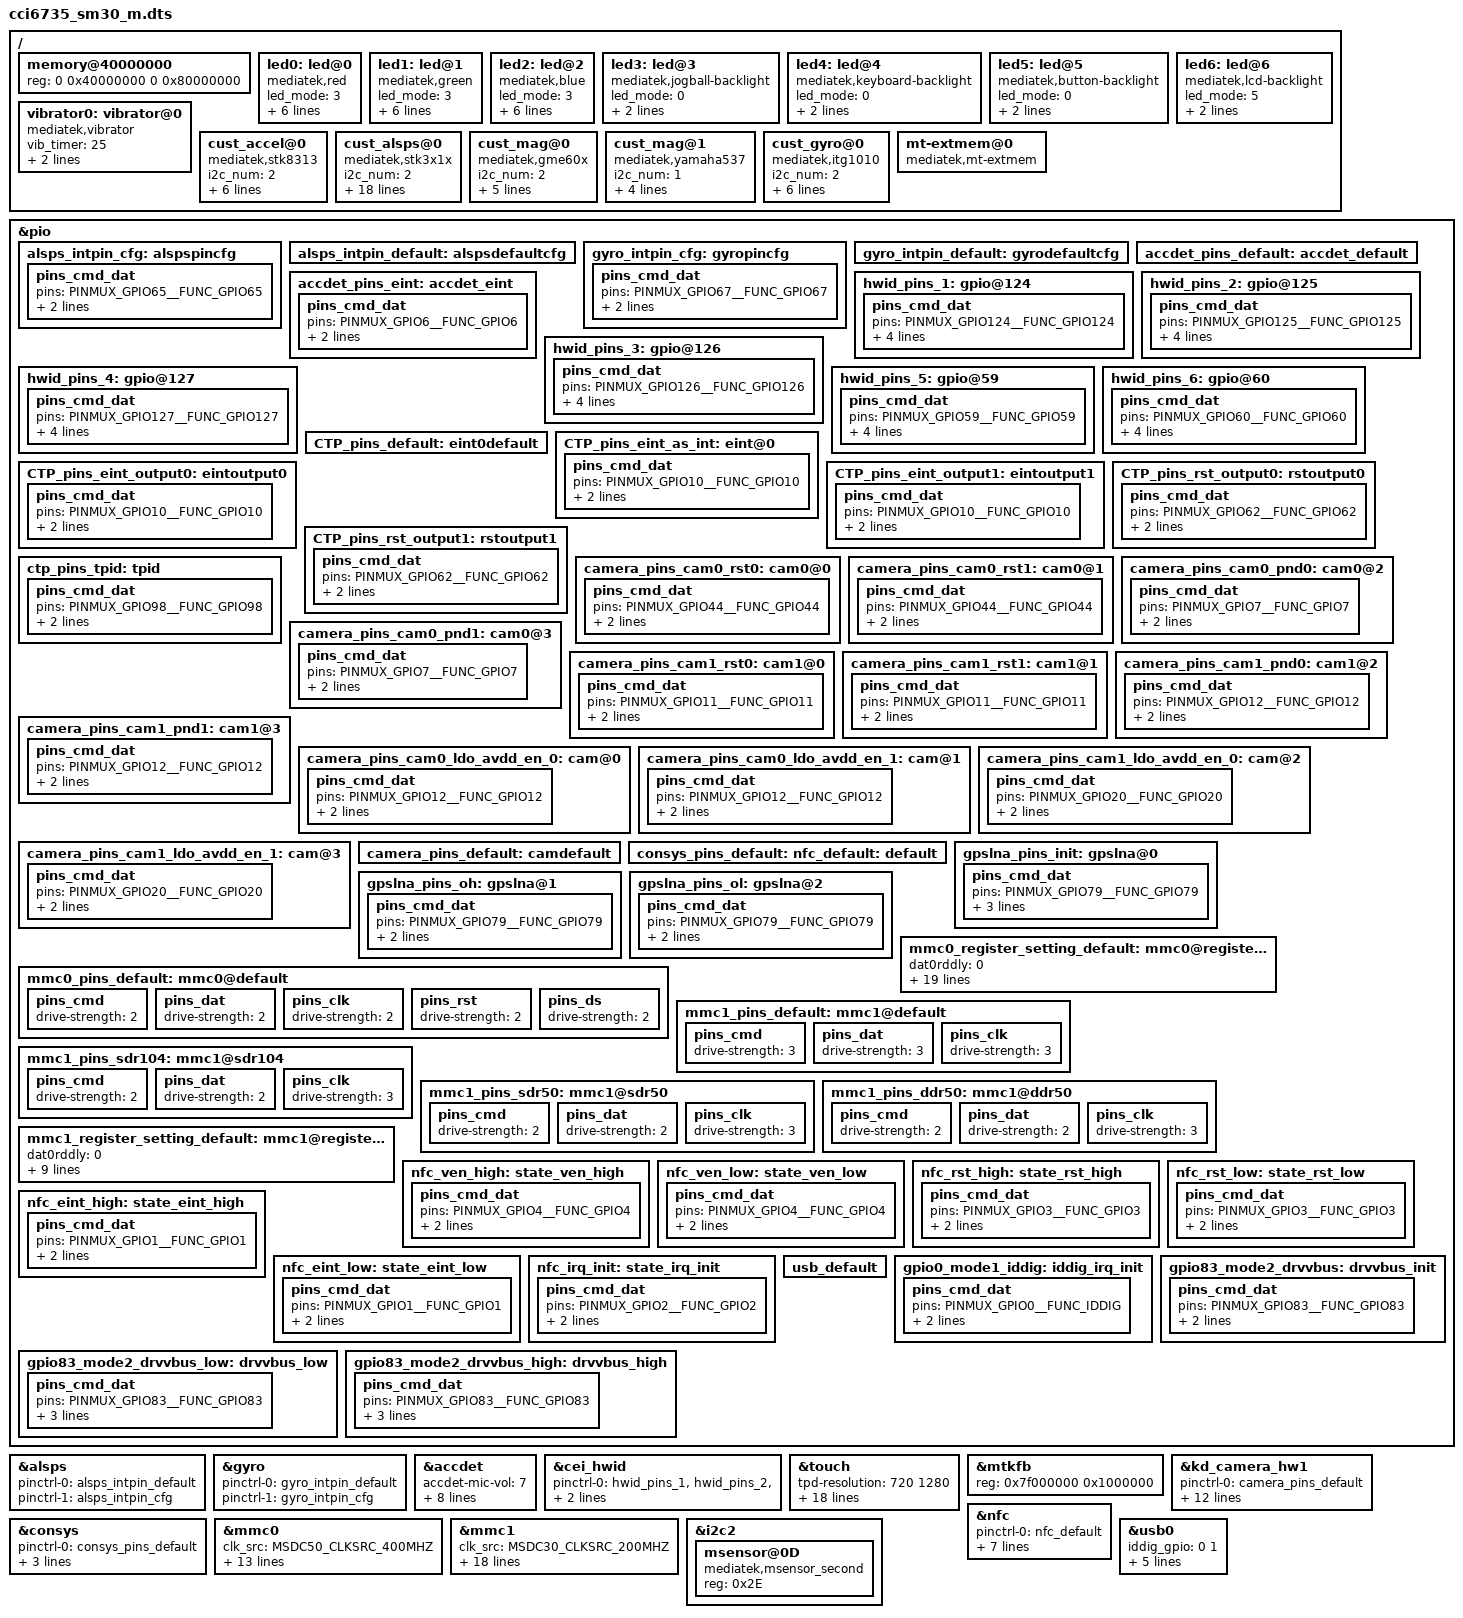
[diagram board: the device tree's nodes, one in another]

/dts-v1/;

#include "mt6735.dtsi"
#include "cust.dtsi"

/ {
	memory@40000000 {
		device_type = "memory";
		reg = <0 0x40000000 0 0x80000000>;
	};

	led0:led@0 {
		compatible = "mediatek,red";
		led_mode = <3>;
		data = <1>;
		pwm_config = <0 0 0 0 0>;
		cei,pwm_currents = <0 0 0 0 0 0 0 0 0 0 0 0 0 0 0 0 0 0 0 0 0 0 0 0 0 0 0 0 0 0 0 0 0 0 0 0 0 0 0 0 0 0 0 2 2 1 4 1 1 1 1 2 2 1 1 1 1 1 1 2 2 1 1 1 1 1 1 2 2 1 1 1 1 4 1 2 2 1 1 1 1 1 1 2 2 1 4 2 2 3 3 2 2 4 4 2 2 2 2 2 2 3 3 2 2 3 3 2 2 2 2 2 2 4 4 2 2 3 3 2 2 3 3 2 2 4 4 2 2 2 3 3 3 3 5 5 5 3 3 4 4 4 3 3 3 4 4 4 3 3 5 5 4 4 3 3 3 3 3 3 3 3 3 3 3 3 4 5 5 3 3 3 4 4 5 5 5 5 4 4 4 4 5 5 5 4 4 4 4 5 5 5 4 4 4 4 4 4 4 4 4 4 4 4 4 4 4 5 5 5 4 4 4 4 5 5 5 5 5 5 5 5 5 5 5 5 5 5 5 5 5 5 5 5 5 5 5 5 5 5 5 5 5 5 5 5 5 5 5 5 5 5 5 5 5 5>;
		cei,pwm_dutys = <0 1 2 2 3 4 5 5 6 7 8 8 9 10 11 11 12 13 14 14 15 16 17 17 18 19 20 20 21 22 23 23 24 25 26 26 27 28 29 29 30 31 32 11 11 17 7 18 18 19 19 13 13 20 20 21 21 22 22 15 15 23 23 24 24 25 25 17 17 26 26 27 27 11 28 19 19 29 29 30 30 31 31 21 21 32 13 22 22 17 17 23 23 14 14 24 24 24 25 25 25 19 19 26 26 20 20 27 27 27 28 28 28 17 17 29 29 22 22 30 30 23 23 31 31 19 19 32 32 32 25 25 25 25 17 17 17 26 26 21 21 21 27 27 27 22 22 22 28 28 19 19 23 23 29 29 29 30 30 30 30 30 31 31 31 31 25 21 21 32 32 32 26 26 22 22 22 22 27 27 27 27 23 23 23 28 28 28 28 24 24 24 29 29 29 29 30 30 30 30 30 30 30 31 31 31 31 26 26 26 32 32 32 32 27 27 27 27 27 28 28 28 28 28 28 28 28 29 29 29 29 29 29 29 29 30 30 30 30 30 30 30 30 31 31 31 31 31 31 31 31 32 32 32 32 32>;
	};
	led1:led@1 {
		compatible = "mediatek,green";
		led_mode = <3>;
		data = <2>;
		pwm_config = <0 0 0 0 0>;
		cei,pwm_currents = <0 0 0 0 0 0 0 0 0 0 0 0 0 0 0 0 0 0 0 0 0 0 0 0 0 0 0 0 0 0 0 0 0 0 0 0 0 0 0 0 0 0 0 2 2 1 4 1 1 1 1 2 2 1 1 1 1 1 1 2 2 1 1 1 1 1 1 2 2 1 1 1 1 4 1 2 2 1 1 1 1 1 1 2 2 1 4 2 2 3 3 2 2 4 4 2 2 2 2 2 2 3 3 2 2 3 3 2 2 2 2 2 2 4 4 2 2 3 3 2 2 3 3 2 2 4 4 2 2 2 3 3 3 3 5 5 5 3 3 4 4 4 3 3 3 4 4 4 3 3 5 5 4 4 3 3 3 3 3 3 3 3 3 3 3 3 4 5 5 3 3 3 4 4 5 5 5 5 4 4 4 4 5 5 5 4 4 4 4 5 5 5 4 4 4 4 4 4 4 4 4 4 4 4 4 4 4 5 5 5 4 4 4 4 5 5 5 5 5 5 5 5 5 5 5 5 5 5 5 5 5 5 5 5 5 5 5 5 5 5 5 5 5 5 5 5 5 5 5 5 5 5 5 5 5 5>;
		cei,pwm_dutys = <0 1 2 2 3 4 5 5 6 7 8 8 9 10 11 11 12 13 14 14 15 16 17 17 18 19 20 20 21 22 23 23 24 25 26 26 27 28 29 29 30 31 32 11 11 17 7 18 18 19 19 13 13 20 20 21 21 22 22 15 15 23 23 24 24 25 25 17 17 26 26 27 27 11 28 19 19 29 29 30 30 31 31 21 21 32 13 22 22 17 17 23 23 14 14 24 24 24 25 25 25 19 19 26 26 20 20 27 27 27 28 28 28 17 17 29 29 22 22 30 30 23 23 31 31 19 19 32 32 32 25 25 25 25 17 17 17 26 26 21 21 21 27 27 27 22 22 22 28 28 19 19 23 23 29 29 29 30 30 30 30 30 31 31 31 31 25 21 21 32 32 32 26 26 22 22 22 22 27 27 27 27 23 23 23 28 28 28 28 24 24 24 29 29 29 29 30 30 30 30 30 30 30 31 31 31 31 26 26 26 32 32 32 32 27 27 27 27 27 28 28 28 28 28 28 28 28 29 29 29 29 29 29 29 29 30 30 30 30 30 30 30 30 31 31 31 31 31 31 31 31 32 32 32 32 32>;

	};
	led2:led@2 {
		compatible = "mediatek,blue";
		led_mode = <3>;
		data = <2>;
		pwm_config = <0 0 0 0 0>;
		cei,pwm_currents = <0 0 0 0 0 0 0 0 0 0 0 0 0 0 0 0 0 0 0 0 0 0 0 0 0 0 0 0 0 0 0 0 0 0 0 0 0 0 0 0 0 0 0 2 2 1 4 1 1 1 1 2 2 1 1 1 1 1 1 2 2 1 1 1 1 1 1 2 2 1 1 1 1 4 1 2 2 1 1 1 1 1 1 2 2 1 4 2 2 3 3 2 2 4 4 2 2 2 2 2 2 3 3 2 2 3 3 2 2 2 2 2 2 4 4 2 2 3 3 2 2 3 3 2 2 4 4 2 2 2 3 3 3 3 5 5 5 3 3 4 4 4 3 3 3 4 4 4 3 3 5 5 4 4 3 3 3 3 3 3 3 3 3 3 3 3 4 5 5 3 3 3 4 4 5 5 5 5 4 4 4 4 5 5 5 4 4 4 4 5 5 5 4 4 4 4 4 4 4 4 4 4 4 4 4 4 4 5 5 5 4 4 4 4 5 5 5 5 5 5 5 5 5 5 5 5 5 5 5 5 5 5 5 5 5 5 5 5 5 5 5 5 5 5 5 5 5 5 5 5 5 5 5 5 5 5>;
		cei,pwm_dutys = <0 1 2 2 3 4 5 5 6 7 8 8 9 10 11 11 12 13 14 14 15 16 17 17 18 19 20 20 21 22 23 23 24 25 26 26 27 28 29 29 30 31 32 11 11 17 7 18 18 19 19 13 13 20 20 21 21 22 22 15 15 23 23 24 24 25 25 17 17 26 26 27 27 11 28 19 19 29 29 30 30 31 31 21 21 32 13 22 22 17 17 23 23 14 14 24 24 24 25 25 25 19 19 26 26 20 20 27 27 27 28 28 28 17 17 29 29 22 22 30 30 23 23 31 31 19 19 32 32 32 25 25 25 25 17 17 17 26 26 21 21 21 27 27 27 22 22 22 28 28 19 19 23 23 29 29 29 30 30 30 30 30 31 31 31 31 25 21 21 32 32 32 26 26 22 22 22 22 27 27 27 27 23 23 23 28 28 28 28 24 24 24 29 29 29 29 30 30 30 30 30 30 30 31 31 31 31 26 26 26 32 32 32 32 27 27 27 27 27 28 28 28 28 28 28 28 28 29 29 29 29 29 29 29 29 30 30 30 30 30 30 30 30 31 31 31 31 31 31 31 31 32 32 32 32 32>;

	};
	led3:led@3 {
		compatible = "mediatek,jogball-backlight";
		led_mode = <0>;
		data = <1>;
		pwm_config = <0 0 0 0 0>;
	};
	led4:led@4 {
		compatible = "mediatek,keyboard-backlight";
		led_mode = <0>;
		data = <1>;
		pwm_config = <0 0 0 0 0>;
	};
	led5:led@5 {
		compatible = "mediatek,button-backlight";
		led_mode = <0>;
		data = <1>;
		pwm_config = <0 0 0 0 0>;
	};
	led6:led@6 {
		compatible = "mediatek,lcd-backlight";
		led_mode = <5>;
		data = <1>;
		pwm_config = <0 0 0 0 0>;
	};
	vibrator0:vibrator@0 {
		compatible = "mediatek,vibrator";
		vib_timer = <25>;
		vib_limit = <9>;
		vib_vol= <6>;
	};
 /* sensor standardization */
		cust_accel@0 {
		compatible				= "mediatek,stk8313";
		i2c_num				= <2>;
		i2c_addr				= <0x22 0 0 0>;
		direction				= <6>;
		power_id				= <0xffff>;
		power_vol				= <0>;
		firlen					= <0>;
		is_batch_supported			= <0>;
		};

		cust_alsps@0 {
		compatible				= "mediatek,stk3x1x";
		i2c_num				= <2>;
		i2c_addr				= <0x48 0 0 0>;
		polling_mode_ps			= <0>;
		polling_mode_als		= <1>;
		power_id				= <0xffff>;
		power_vol				= <0>;
		als_level = <5 9 36 59 82 132 205 273 500 845 1136 1545 2364 4655 6982>;
		als_value = <0 10 40 65 90 145 225 300 550 930 1250 1700 2600 5120 7680 10240>;
		ps_threshold_high		=  <1650>;
		ps_threshold_low		=  <1600>;
		is_batch_supported_ps	= <1>;
		is_batch_supported_als	= <1>;
		state_val = <0x00>;               /* disable all */
		psctrl_val = <0x31>;     /* ps_persistance=4, ps_gain=64X, PS_IT=0.391ms */
		alsctrl_val = <0x39>;    /* als_persistance=1, als_gain=64X, ALS_IT=100ms */
		ledctrl_val = <0xff>;    /* 50mA IRDR, 64/64 LED duty */
		wait_val = <0x09>;
		};

		cust_mag@0 {
		compatible				= "mediatek,gme60x";
		i2c_num				= <2>;
		i2c_addr				= <0x0D 0 0 0>;
		direction				= <0>;
		power_id				= <0xffff>;
		power_vol				= <0>;
		is_batch_supported	= <0>;
		};

/*jonny e-compass 2nd S*/
		cust_mag@1 {
		compatible			= "mediatek,yamaha537";
		i2c_num				= <1>;
		i2c_addr			= <0x2E 0 0 0>;
		direction			= <2>;
		power_id			= <0xffff>;
		power_vol			= <0>;
		/* is_batch_supported		= <0>; */
		};
/*jonny e-compass 2nd E*/

		cust_gyro@0 {
		compatible				= "mediatek,itg1010";
		i2c_num				= <2>;
		i2c_addr				= <0x68 0 0 0>;
		direction				= <3>;
		power_id				= <0xffff>;
		power_vol				= <0>;
		firlen					= <0>;
		is_batch_supported	= <0>;
		};

	mt-extmem@0 {
		compatible = "mediatek,mt-extmem";
	};
};
/* sensor gpio standization */
&pio {
	alsps_intpin_cfg: alspspincfg {

	    pins_cmd_dat {
			pins = <PINMUX_GPIO65__FUNC_GPIO65>;
			slew-rate = <0>;
			bias-pull-up = <00>;
		};
	};

	alsps_intpin_default: alspsdefaultcfg {

	};

	gyro_intpin_cfg: gyropincfg {

	    pins_cmd_dat {
			pins = <PINMUX_GPIO67__FUNC_GPIO67>;
			slew-rate = <0>;
			bias-pull-down = <00>;
		};
	};

	gyro_intpin_default: gyrodefaultcfg {

	};
};
&alsps {
	pinctrl-names = "pin_default", "pin_cfg";
	pinctrl-0 = <&alsps_intpin_default>;
	pinctrl-1 = <&alsps_intpin_cfg>;
	status = "okay";

};

&gyro {
	pinctrl-names = "pin_default", "pin_cfg";
	pinctrl-0 = <&gyro_intpin_default>;
	pinctrl-1 = <&gyro_intpin_cfg>;
	status = "okay";

};
/* sensor end */
&accdet {
		accdet-mic-vol = <7>;
		headset-mode-setting = <0x500 0x200 1 0x1F0 0x800 0x800 0x20>;
		accdet-plugout-debounce = <20>;
		/*1:ACC mode, 2:low cost without in bias, 6:low cost with in bias*/
		accdet-mic-mode = <1>;
		/*0--MD_MAX--UP_MAX--DW_MAX*/
		headset-three-key-threshold = <0 80 220 500>;
		/*0--MD_MAX--VOICE_MAX--UP_MAX--DW_MAX*/
		headset-four-key-threshold = <0 58 100 192 450>;
		pinctrl-names = "default", "state_eint_as_int";
		pinctrl-0 = <&accdet_pins_default>;
		pinctrl-1 = <&accdet_pins_eint>;
};
&pio {
	accdet_pins_default: accdet_default {
	};
	accdet_pins_eint: accdet_eint {
		pins_cmd_dat {
			pins = <PINMUX_GPIO6__FUNC_GPIO6>;
			slew-rate = <0>;        /* DIRECTION: INPUT */
			bias-disable;           /* PULL DISABLE */
		};
	};
};

/* HWID start */
&cei_hwid {
   pinctrl-names = "cei_hwid_pinctrl_active";
   pinctrl-0 = <&hwid_pins_1 &hwid_pins_2 &hwid_pins_3 &hwid_pins_4 &hwid_pins_5 &hwid_pins_6>;
   status = "okay";
};
&pio {
	hwid_pins_1: gpio@124 {
		pins_cmd_dat {
			pins = <PINMUX_GPIO124__FUNC_GPIO124>;
			slew-rate = <0>;      /* DIRECTION: INPUT */
			bias-disable;           /* PULL DISABLE */
			output-low;             /* Only When direction out is effective */  
			input-schmitt-enable = <0>;
		};
	};
	hwid_pins_2: gpio@125 {
		pins_cmd_dat {
			pins = <PINMUX_GPIO125__FUNC_GPIO125>;
			slew-rate = <0>;
			bias-disable;
			output-low;
			input-schmitt-enable = <0>;
		};
	};
	hwid_pins_3: gpio@126 {
		pins_cmd_dat {
			pins = <PINMUX_GPIO126__FUNC_GPIO126>;
			slew-rate = <0>;
			bias-disable;
			output-low;
			input-schmitt-enable = <0>;
		};
	};
	hwid_pins_4: gpio@127 {
		pins_cmd_dat {
			pins = <PINMUX_GPIO127__FUNC_GPIO127>;
			slew-rate = <0>;
			bias-disable;
			output-low;
			input-schmitt-enable = <0>;
		};
	};
	hwid_pins_5: gpio@59 {
		pins_cmd_dat {
			pins = <PINMUX_GPIO59__FUNC_GPIO59>;
			slew-rate = <0>;
			bias-disable;
			output-low;
			input-schmitt-enable = <0>;
		};
	};
	hwid_pins_6: gpio@60 {
		pins_cmd_dat {
			pins = <PINMUX_GPIO60__FUNC_GPIO60>;
			slew-rate = <0>;
			bias-disable;
			output-low;
			input-schmitt-enable = <0>;
		};
	};
};
/* HWID end */

&touch {
	tpd-resolution = <720 1280>;
	use-tpd-button = <0>;
	tpd-key-num = <3>;
	tpd-key-local= <139 172 158 0>;
	tpd-key-dim-local = <90 883 100 40 230 883 100 40 370 883 100 40 0 0 0 0>;
	tpd-max-touch-num = <5>;
	tpd-filter-enable = <1>;
	tpd-filter-pixel-density = <124>;
	tpd-filter-custom-prameters = <0 0 0 0 0 0 0 0 0 0 0 0>;
	tpd-filter-custom-speed = <0 0 0>;
	pinctrl-names = "default", "state_eint_as_int", "state_eint_output0", "state_eint_output1",
		"state_rst_output0", "state_rst_output1", "state_tpid";
	pinctrl-0 = <&CTP_pins_default>;
	pinctrl-1 = <&CTP_pins_eint_as_int>;
	pinctrl-2 = <&CTP_pins_eint_output0>;
	pinctrl-3 = <&CTP_pins_eint_output1>;
	pinctrl-4 = <&CTP_pins_rst_output0>;
	pinctrl-5 = <&CTP_pins_rst_output1>;
	pinctrl-6 = <&ctp_pins_tpid>;
	status = "okay";
};

&mtkfb {
	reg = <0x7f000000 0x1000000>;
};


&pio {
	CTP_pins_default: eint0default {
	};
	CTP_pins_eint_as_int: eint@0 {
		pins_cmd_dat {
			pins = <PINMUX_GPIO10__FUNC_GPIO10>;
			slew-rate = <0>;
			/*bias-disable;*/
			bias-pull-up = <00>;
		};
	};
	CTP_pins_eint_output0: eintoutput0 {
		pins_cmd_dat {
			pins = <PINMUX_GPIO10__FUNC_GPIO10>;
			slew-rate = <1>;
			output-low;
		};
	};
	CTP_pins_eint_output1: eintoutput1 {
		pins_cmd_dat {
			pins = <PINMUX_GPIO10__FUNC_GPIO10>;
			slew-rate = <1>;
			output-high;
		};
	};
	CTP_pins_rst_output0: rstoutput0 {
		pins_cmd_dat {
			pins = <PINMUX_GPIO62__FUNC_GPIO62>;
			slew-rate = <1>;
			output-low;
		};
	};
	CTP_pins_rst_output1: rstoutput1 {
		pins_cmd_dat {
			pins = <PINMUX_GPIO62__FUNC_GPIO62>;
			slew-rate = <1>;
			output-high;
		};
	};
	ctp_pins_tpid: tpid {
		pins_cmd_dat {
			pins = <PINMUX_GPIO98__FUNC_GPIO98>;
			slew-rate = <0>;
			bias-pull-up = <00>;
		};
	};
};
/* TOUCH end */

/* CAMERA GPIO standardization */
&pio {
	camera_pins_cam0_rst0: cam0@0 {
		pins_cmd_dat {
			pins = <PINMUX_GPIO44__FUNC_GPIO44>;/*GPIO_CAMERA_CMRST_PIN*/
			slew-rate = <1>; /*direction 0:in, 1:out*/
			output-low;/*direction out used only. output_low or high*/
		};
	};
	camera_pins_cam0_rst1: cam0@1 {
		pins_cmd_dat {
			pins = <PINMUX_GPIO44__FUNC_GPIO44>;/*GPIO_CAMERA_CMRST_PIN*/
			slew-rate = <1>;
			output-high;
		};
	};
	camera_pins_cam0_pnd0: cam0@2 {
		pins_cmd_dat {
			pins = <PINMUX_GPIO7__FUNC_GPIO7>;/*GPIO_CAMERA_CMPDN_PIN*/
			slew-rate = <1>;
			output-low;
		};
	};
	camera_pins_cam0_pnd1: cam0@3 {
		pins_cmd_dat {
			pins = <PINMUX_GPIO7__FUNC_GPIO7>;/*GPIO_CAMERA_CMPDN_PIN*/
			slew-rate = <1>;
			output-high;
		};
	};
	camera_pins_cam1_rst0: cam1@0 {
		pins_cmd_dat {
			pins = <PINMUX_GPIO11__FUNC_GPIO11>;/*GPIO_CAMERA_CMRST1_PIN*/
			slew-rate = <1>; /*direction 0:in, 1:out*/
			output-low;/*direction out used only. output_low or high*/
		};
	};
	camera_pins_cam1_rst1: cam1@1 {
		pins_cmd_dat {
			pins = <PINMUX_GPIO11__FUNC_GPIO11>;/*GPIO_CAMERA_CMRST1_PIN*/
			slew-rate = <1>;
			output-high;
		};
	};
	camera_pins_cam1_pnd0: cam1@2 {
		pins_cmd_dat {
			pins = <PINMUX_GPIO12__FUNC_GPIO12>;/*GPIO_CAMERA_CMPDN1_PIN*/
			slew-rate = <1>;
			output-low;
		};
	};
	camera_pins_cam1_pnd1: cam1@3 {
		pins_cmd_dat {
			pins = <PINMUX_GPIO12__FUNC_GPIO12>;/*GPIO_CAMERA_CMPDN1_PIN*/
			slew-rate = <1>;
			output-high;
		};
	};
	camera_pins_cam0_ldo_avdd_en_0: cam@0 {
		pins_cmd_dat {
			pins = <PINMUX_GPIO12__FUNC_GPIO12>;
			slew-rate = <1>;
			output-low;
		};
	};
	camera_pins_cam0_ldo_avdd_en_1: cam@1 {
		pins_cmd_dat {
			pins = <PINMUX_GPIO12__FUNC_GPIO12>;
			slew-rate = <1>;
			output-high;
		};
	};
	camera_pins_cam1_ldo_avdd_en_0: cam@2 {
		pins_cmd_dat {
			pins = <PINMUX_GPIO20__FUNC_GPIO20>;
			slew-rate = <1>;
			output-low;
		};
	};
	camera_pins_cam1_ldo_avdd_en_1: cam@3 {
		pins_cmd_dat {
			pins = <PINMUX_GPIO20__FUNC_GPIO20>;
			slew-rate = <1>;
			output-high;
		};
	};
	camera_pins_default: camdefault {

	};
};

&kd_camera_hw1 {
	pinctrl-names = "default", "cam0_rst0", "cam0_rst1", "cam0_pnd0", "cam0_pnd1",
	"cam1_rst0", "cam1_rst1", "cam1_pnd0", "cam1_pnd1",
	"cam0_ldo_avdd_en_0", "cam0_ldo_avdd_en_1",
	"cam1_ldo_avdd_en_0", "cam1_ldo_avdd_en_1";
	pinctrl-0 = <&camera_pins_default>;
	pinctrl-1 = <&camera_pins_cam0_rst0>;
	pinctrl-2 = <&camera_pins_cam0_rst1>;
	pinctrl-3 = <&camera_pins_cam0_pnd0>;
	pinctrl-4 = <&camera_pins_cam0_pnd1>;
	pinctrl-5 = <&camera_pins_cam1_rst0>;
	pinctrl-6 = <&camera_pins_cam1_rst1>;
	pinctrl-7 = <&camera_pins_cam1_pnd0>;
	pinctrl-8 = <&camera_pins_cam1_pnd1>;
	pinctrl-9 = <&camera_pins_cam0_ldo_avdd_en_0>;
	pinctrl-10 = <&camera_pins_cam0_ldo_avdd_en_1>;
	pinctrl-11 = <&camera_pins_cam1_ldo_avdd_en_0>;
	pinctrl-12 = <&camera_pins_cam1_ldo_avdd_en_1>;
	status = "okay";

};
/* CAMERA GPIO end */

/* CONSYS GPIO standardization */
&pio {
	consys_pins_default: default {

	};

	gpslna_pins_init: gpslna@0 {

	    pins_cmd_dat {
			pins = <PINMUX_GPIO79__FUNC_GPIO79>;
			slew-rate = <0>;
			bias-disable;
			output-low;
		};
	};

	gpslna_pins_oh: gpslna@1 {

	    pins_cmd_dat {
			pins = <PINMUX_GPIO79__FUNC_GPIO79>;
			slew-rate = <1>;
			output-high;
		};
	};

	gpslna_pins_ol: gpslna@2 {

	    pins_cmd_dat {
			pins = <PINMUX_GPIO79__FUNC_GPIO79>;
			slew-rate = <1>;
			output-low;
		};
	};

};

&consys {
	pinctrl-names = "default", "gps_lna_state_init", "gps_lna_state_oh", "gps_lna_state_ol";
	pinctrl-0 = <&consys_pins_default>;
	pinctrl-1 = <&gpslna_pins_init>;
	pinctrl-2 = <&gpslna_pins_oh>;
	pinctrl-3 = <&gpslna_pins_ol>;
	status = "okay";

};
/* CONSYS end */

/* mmc start */
&mmc0 {
		clk_src = /bits/ 8 <MSDC50_CLKSRC_400MHZ>;
		bus-width = <8>;
		max-frequency = <200000000>;
		cap-mmc-highspeed;
		msdc-sys-suspend;
		mmc-ddr-1_8v;
		mmc-hs200-1_8v;
		mmc-hs400-1_8v;
		non-removable;
		pinctl = <&mmc0_pins_default>;
		register_setting = <&mmc0_register_setting_default>;
		host_function = /bits/ 8 <MSDC_EMMC>;
		bootable;
		status = "okay";
};

&mmc1 {
		clk_src = /bits/ 8 <MSDC30_CLKSRC_200MHZ>;
		bus-width = <4>;
		max-frequency = <200000000>;
		msdc-sys-suspend;
		cap-sd-highspeed;
		sd-uhs-sdr12;
		sd-uhs-sdr25;
		sd-uhs-sdr50;
		sd-uhs-sdr104;
		sd-uhs-ddr50;
		pinctl = <&mmc1_pins_default>;
		pinctl_sdr104 = <&mmc1_pins_sdr104>;
		pinctl_sdr50 = <&mmc1_pins_sdr50>;
		pinctl_ddr50 = <&mmc1_pins_ddr50>;
		register_setting = <&mmc1_register_setting_default>;
		host_function = /bits/ 8 <MSDC_SD>;
		cd_level = /bits/ 8 <MSDC_CD_HIGH>;
		cd-gpios = <&pio 5 0>;
		status = "okay";
};

&pio {
	mmc0_pins_default: mmc0@default {
			pins_cmd {
				drive-strength = /bits/ 8 <2>;
			};
			pins_dat {
				drive-strength = /bits/ 8 <2>;
			};
			pins_clk {
				drive-strength = /bits/ 8 <2>;
			};
			pins_rst {
				drive-strength = /bits/ 8 <2>;
			};
			pins_ds {
				drive-strength = /bits/ 8 <2>;
			};
	};

	mmc0_register_setting_default: mmc0@register_default {
		dat0rddly      = /bits/ 8 <0>;
		dat1rddly      = /bits/ 8 <0>;
		dat2rddly      = /bits/ 8 <0>;
		dat3rddly      = /bits/ 8 <0>;
		dat4rddly      = /bits/ 8 <0>;
		dat5rddly      = /bits/ 8 <0>;
		dat6rddly      = /bits/ 8 <0>;
		dat7rddly      = /bits/ 8 <0>;
		datwrddly      = /bits/ 8 <0>;
		cmdrrddly      = /bits/ 8 <0>;
		cmdrddly       = /bits/ 8 <0>;
		cmd_edge = /bits/ 8 <MSDC_SMPL_FALLING>;
		rdata_edge = /bits/ 8 <MSDC_SMPL_FALLING>;
		wdata_edge = /bits/ 8 <MSDC_SMPL_FALLING>;

		ett-hs200-cells = <12>;
		ett-hs200-default = <OFFSET_MSDC_PATCH_BIT0	MSDC_PB0_INT_DAT_LATCH_CK_SEL 0x0
			OFFSET_MSDC_PATCH_BIT0	MSDC_PB0_CKGEN_MSDC_DLY_SEL   0x0
			OFFSET_MSDC_PATCH_BIT1	MSDC_PB1_CMD_RSP_TA_CNTR      0x1
			OFFSET_MSDC_IOCON		MSDC_IOCON_RSPL               0x0
			OFFSET_MSDC_PAD_TUNE0	MSDC_PAD_TUNE0_CMDRDLY        0x7
			OFFSET_MSDC_PAD_TUNE0	MSDC_PAD_TUNE0_CMDRRDLY       0xb
			OFFSET_MSDC_PATCH_BIT1		MSDC_PB1_WRDAT_CRCS_TA_CNTR   0x1
			OFFSET_MSDC_PAD_TUNE0	MSDC_PAD_TUNE0_DATWRDLY       0xb
			OFFSET_MSDC_IOCON			MSDC_IOCON_W_D0SPL            0x0
			OFFSET_MSDC_DAT_RDDLY0		MSDC_DAT_RDDLY0_D0            0x7
			OFFSET_MSDC_PAD_TUNE0	MSDC_PAD_TUNE0_DATRRDLY       0x9
			OFFSET_MSDC_IOCON		MSDC_IOCON_R_D_SMPL           0x0>;

		ett-hs400-cells = <8>;
		ett-hs400-default = <OFFSET_MSDC_PATCH_BIT0	MSDC_PB0_INT_DAT_LATCH_CK_SEL	0x0
			OFFSET_MSDC_PATCH_BIT0		MSDC_PB0_CKGEN_MSDC_DLY_SEL		0x0
			OFFSET_EMMC50_PAD_DS_TUNE	MSDC_EMMC50_PAD_DS_TUNE_DLY1	0x2
			OFFSET_EMMC50_PAD_DS_TUNE	MSDC_EMMC50_PAD_DS_TUNE_DLY3	0x10
			OFFSET_MSDC_PATCH_BIT1			MSDC_PB1_CMD_RSP_TA_CNTR	0x1
			OFFSET_MSDC_IOCON		MSDC_IOCON_RSPL				0x0
			OFFSET_MSDC_PAD_TUNE0			MSDC_PAD_TUNE0_CMDRDLY		0x6
			OFFSET_MSDC_PAD_TUNE0		MSDC_PAD_TUNE0_CMDRRDLY		0x6>;
	};

	mmc1_pins_default: mmc1@default {
			pins_cmd {
				drive-strength = /bits/ 8 <3>;
			};
			pins_dat {
				drive-strength = /bits/ 8 <3>;
			};
			pins_clk {
				drive-strength = /bits/ 8 <3>;
			};
	};

	mmc1_pins_sdr104: mmc1@sdr104 {
			pins_cmd {
				drive-strength = /bits/ 8 <2>;
			};
			pins_dat {
				drive-strength = /bits/ 8 <2>;
			};
			pins_clk {
				drive-strength = /bits/ 8 <3>;
			};
	};

	mmc1_pins_sdr50: mmc1@sdr50 {
			pins_cmd {
				drive-strength = /bits/ 8 <2>;
			};
			pins_dat {
				drive-strength = /bits/ 8 <2>;
			};
			pins_clk {
				drive-strength = /bits/ 8 <3>;
			};
	};

	mmc1_pins_ddr50: mmc1@ddr50 {
			pins_cmd {
				drive-strength = /bits/ 8 <2>;
			};
			pins_dat {
				drive-strength = /bits/ 8 <2>;
			};
			pins_clk {
				drive-strength = /bits/ 8 <3>;
			};
	};

	mmc1_register_setting_default: mmc1@register_default {
				dat0rddly      = /bits/ 8 <0>;
				dat1rddly      = /bits/ 8 <0>;
				dat2rddly      = /bits/ 8 <0>;
				dat3rddly      = /bits/ 8 <0>;
				datwrddly      = /bits/ 8 <0>;
				cmdrrddly      = /bits/ 8 <0>;
				cmdrddly       = /bits/ 8 <0>;
				cmd_edge = /bits/ 8 <MSDC_SMPL_FALLING>;
				rdata_edge = /bits/ 8 <MSDC_SMPL_FALLING>;
				wdata_edge = /bits/ 8 <MSDC_SMPL_FALLING>;
	};
};
/* mmc end */

/* NFC GPIO standardization */
&pio {
	nfc_default: default {

	};

	nfc_ven_high: state_ven_high {
		pins_cmd_dat {
			pins = <PINMUX_GPIO4__FUNC_GPIO4>;
			slew-rate = <1>;
			output-high;
		};
	};

	nfc_ven_low: state_ven_low {
		pins_cmd_dat {
			pins = <PINMUX_GPIO4__FUNC_GPIO4>;
			slew-rate = <1>;
			output-low;
		};
	};

	nfc_rst_high: state_rst_high {
		pins_cmd_dat {
			pins = <PINMUX_GPIO3__FUNC_GPIO3>;
			slew-rate = <1>;
			output-high;
		};
	};

	nfc_rst_low: state_rst_low {
		pins_cmd_dat {
			pins = <PINMUX_GPIO3__FUNC_GPIO3>;
			slew-rate = <1>;
			output-low;
		};
	};

	nfc_eint_high: state_eint_high {
		pins_cmd_dat {
			pins = <PINMUX_GPIO1__FUNC_GPIO1>;
			slew-rate = <1>;
			output-high;
		};
	};

	nfc_eint_low: state_eint_low {
		pins_cmd_dat {
			pins = <PINMUX_GPIO1__FUNC_GPIO1>;
			slew-rate = <1>;
			output-low;
		};
	};

	nfc_irq_init: state_irq_init {
		pins_cmd_dat {
			pins = <PINMUX_GPIO2__FUNC_GPIO2>;
			slew-rate = <0>;
			bias-pull-down = <00>;
		};
	};
};

&nfc {
	pinctrl-names = "default", "ven_high", "ven_low", "rst_high", "rst_low", "eint_high", "eint_low", "irq_init";
	pinctrl-0 = <&nfc_default>;
	pinctrl-1 = <&nfc_ven_high>;
	pinctrl-2 = <&nfc_ven_low>;
	pinctrl-3 = <&nfc_rst_high>;
	pinctrl-4 = <&nfc_rst_low>;
	pinctrl-5 = <&nfc_eint_high>;
	pinctrl-6 = <&nfc_eint_low>;
	pinctrl-7 = <&nfc_irq_init>;
	status = "okay";
};
/* NFC end */

/* USB GPIO Kernal Standardization start */
&pio {
	usb_default: usb_default {
	};

	gpio0_mode1_iddig: iddig_irq_init {
		pins_cmd_dat {
			pins = <PINMUX_GPIO0__FUNC_IDDIG>;
			slew-rate = <0>;
			bias-pull-up = <00>;
		};
	};

	gpio83_mode2_drvvbus: drvvbus_init {
		pins_cmd_dat {
			pins = <PINMUX_GPIO83__FUNC_GPIO83>;
			slew-rate = <1>;
			bias-pull-down = <00>;
		};
	};

	gpio83_mode2_drvvbus_low: drvvbus_low {
		pins_cmd_dat {
			pins = <PINMUX_GPIO83__FUNC_GPIO83>;
			slew-rate = <1>;
			output-low;
			bias-pull-down = <00>;
		};
	};

	gpio83_mode2_drvvbus_high: drvvbus_high {
		pins_cmd_dat {
			pins = <PINMUX_GPIO83__FUNC_GPIO83>;
			slew-rate = <1>;
			output-high;
			bias-pull-down = <00>;
		};
	};
};

/*jonny e-compass 2nd S*/
&i2c2 {
	msensor@0D {
		compatible = "mediatek,msensor_second";
		reg = <0x2E>;
		status = "okay";
	};
};
/*jonny e-compass 2nd E*/

&usb0 {
	iddig_gpio = <0 1>;
	pinctrl-names = "usb_default", "iddig_irq_init", "drvvbus_init", "drvvbus_low", "drvvbus_high";
	pinctrl-0 = <&usb_default>;
	pinctrl-1 = <&gpio0_mode1_iddig>;
	pinctrl-2 = <&gpio83_mode2_drvvbus>;
	pinctrl-3 = <&gpio83_mode2_drvvbus_low>;
	pinctrl-4 = <&gpio83_mode2_drvvbus_high>;
	status = "okay";
};
/* USB GPIO Kernal Standardization end */
